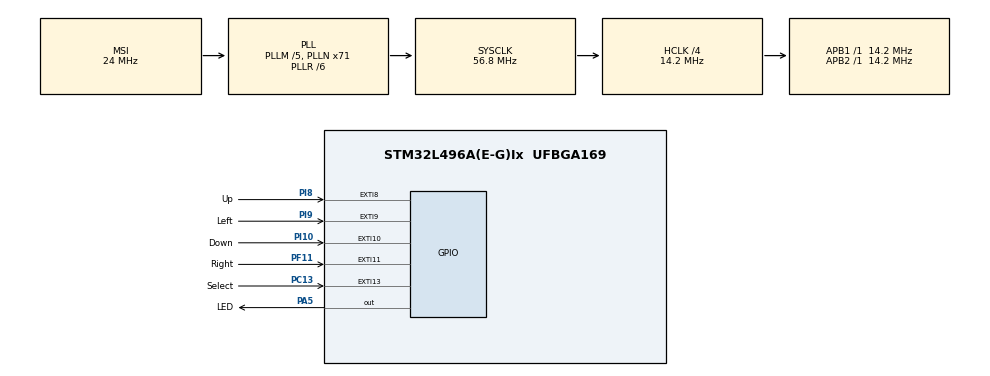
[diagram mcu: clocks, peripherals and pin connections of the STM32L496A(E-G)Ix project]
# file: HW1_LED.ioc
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Mcu.Family=STM32L4
Mcu.Name=STM32L496A(E-G)Ix
Mcu.Package=UFBGA169
NVIC.EXTI15_10_IRQn=true\:0\:0\:false\:false\:true\:true\:true\:true
NVIC.EXTI9_5_IRQn=true\:0\:0\:false\:false\:true\:true\:true\:true
NVIC.PVD_PVM_IRQn=true\:0\:0\:false\:false\:true\:true\:true\:true
NVIC.PriorityGroup=NVIC_PRIORITYGROUP_4
PA5.GPIO_Label=LED
PA5.GPIO_PuPd=GPIO_NOPULL
PA5.GPIO_Speed=GPIO_SPEED_FREQ_HIGH
PA5.Signal=GPIO_Output
PC13.GPIO_Label=Select
PC13.GPIO_PuPd=GPIO_PULLDOWN
PC13.Signal=GPXTI13
PF11.GPIO_Label=Right 
PF11.GPIO_PuPd=GPIO_PULLDOWN
PF11.Signal=GPXTI11
PI10.GPIO_Label=Down 
PI10.GPIO_PuPd=GPIO_PULLDOWN
PI10.Signal=GPXTI10
PI8.GPIO_Label=Up 
PI8.GPIO_PuPd=GPIO_PULLDOWN
PI8.Signal=GPXTI8
PI9.GPIO_Label=Left
PI9.GPIO_PuPd=GPIO_PULLDOWN
PI9.Signal=GPXTI9
ProjectManager.HeapSize=0x200
ProjectManager.StackSize=0x400
ProjectManager.TargetToolchain=STM32CubeIDE
RCC.ADCFreq_Value=48000000
RCC.AHBCLKDivider=RCC_SYSCLK_DIV4
RCC.AHBFreq_Value=14200000
RCC.APB1Freq_Value=14200000
RCC.APB1TimFreq_Value=14200000
RCC.APB2Freq_Value=14200000
RCC.APB2TimFreq_Value=14200000
RCC.CortexFreq_Value=14200000
RCC.HCLKFreq_Value=14200000
RCC.HSE_VALUE=8000000
RCC.HSI48_VALUE=48000000
RCC.HSI_VALUE=16000000
RCC.LSE_VALUE=32768
RCC.MSIClockRange=RCC_MSIRANGE_9
RCC.MSI_VALUE=24000000
RCC.PLLM=5
RCC.PLLN=71
RCC.PLLR=RCC_PLLR_DIV6
RCC.PLLSAI1N=20
RCC.SYSCLKFreq_VALUE=56800000
RCC.SYSCLKSource=RCC_SYSCLKSOURCE_PLLCLK
RCC.USBFreq_Value=48000000
RCC.VCOOutputFreq_Value=340800000
board=STM32L496G-DISCO

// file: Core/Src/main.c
/* USER CODE BEGIN Header */
/**
  ******************************************************************************
  * @file           : main.c
  * @brief          : Main program body
  ******************************************************************************
  * @attention
  *
  * Copyright (c) 2022 STMicroelectronics.
  * All rights reserved.
  *
  * This software is licensed under terms that can be found in the LICENSE file
  * in the root directory of this software component.
  * If no LICENSE file comes with this software, it is provided AS-IS.
  *
  ******************************************************************************
  */
/* USER CODE END Header */
#include "main.h"

void SystemClock_Config(void);
static void MX_GPIO_Init(void);

int main(void)
{

  /* MCU Configuration--------------------------------------------------------*/

  /* Reset of all peripherals, Initializes the Flash interface and the Systick. */
  HAL_Init();

  /* Configure the system clock */
  SystemClock_Config();

  /* Initialize all configured peripherals */
  MX_GPIO_Init();

  /* Infinite loop */
  while (1)
  {

  }
}

void SystemClock_Config(void)
{
  RCC_OscInitTypeDef RCC_OscInitStruct = {0};
  RCC_ClkInitTypeDef RCC_ClkInitStruct = {0};

  /** Configure the main internal regulator output voltage
  */
  if (HAL_PWREx_ControlVoltageScaling(PWR_REGULATOR_VOLTAGE_SCALE1) != HAL_OK)
  {
    Error_Handler();
  }

  /** Initializes the RCC Oscillators according to the specified parameters
  * in the RCC_OscInitTypeDef structure.
  */
  RCC_OscInitStruct.OscillatorType = RCC_OSCILLATORTYPE_MSI;
  RCC_OscInitStruct.MSIState = RCC_MSI_ON;
  RCC_OscInitStruct.MSICalibrationValue = 0;
  RCC_OscInitStruct.MSIClockRange = RCC_MSIRANGE_9;
  RCC_OscInitStruct.PLL.PLLState = RCC_PLL_ON;
  RCC_OscInitStruct.PLL.PLLSource = RCC_PLLSOURCE_MSI;
  RCC_OscInitStruct.PLL.PLLM = 5;
  RCC_OscInitStruct.PLL.PLLN = 71;
  RCC_OscInitStruct.PLL.PLLP = RCC_PLLP_DIV2;
  RCC_OscInitStruct.PLL.PLLQ = RCC_PLLQ_DIV2;
  RCC_OscInitStruct.PLL.PLLR = RCC_PLLR_DIV6;
  if (HAL_RCC_OscConfig(&RCC_OscInitStruct) != HAL_OK)
  {
    Error_Handler();
  }

  /** Initializes the CPU, AHB and APB buses clocks
  */
  RCC_ClkInitStruct.ClockType = RCC_CLOCKTYPE_HCLK|RCC_CLOCKTYPE_SYSCLK
                              |RCC_CLOCKTYPE_PCLK1|RCC_CLOCKTYPE_PCLK2;
  RCC_ClkInitStruct.SYSCLKSource = RCC_SYSCLKSOURCE_PLLCLK;
  RCC_ClkInitStruct.AHBCLKDivider = RCC_SYSCLK_DIV4;
  RCC_ClkInitStruct.APB1CLKDivider = RCC_HCLK_DIV1;
  RCC_ClkInitStruct.APB2CLKDivider = RCC_HCLK_DIV1;

  if (HAL_RCC_ClockConfig(&RCC_ClkInitStruct, FLASH_LATENCY_0) != HAL_OK)
  {
    Error_Handler();
  }
}

static void MX_GPIO_Init(void)
{
  GPIO_InitTypeDef GPIO_InitStruct = {0};

  /* GPIO Ports Clock Enable */
  __HAL_RCC_GPIOI_CLK_ENABLE();
  __HAL_RCC_GPIOC_CLK_ENABLE();
  __HAL_RCC_GPIOA_CLK_ENABLE();
  __HAL_RCC_GPIOF_CLK_ENABLE();

  /*Configure GPIO pin Output Level */
  HAL_GPIO_WritePin(LED_GPIO_Port, LED_Pin, GPIO_PIN_RESET);

  /*Configure GPIO pins : Down_Pin Left_Pin Up_Pin */
  GPIO_InitStruct.Pin = Down_Pin|Left_Pin|Up_Pin;
  GPIO_InitStruct.Mode = GPIO_MODE_IT_RISING;
  GPIO_InitStruct.Pull = GPIO_PULLDOWN;
  HAL_GPIO_Init(GPIOI, &GPIO_InitStruct);

  /*Configure GPIO pin : Select_Pin */
  GPIO_InitStruct.Pin = Select_Pin;
  GPIO_InitStruct.Mode = GPIO_MODE_IT_RISING;
  GPIO_InitStruct.Pull = GPIO_PULLDOWN;
  HAL_GPIO_Init(Select_GPIO_Port, &GPIO_InitStruct);

  /*Configure GPIO pin : LED_Pin */
  GPIO_InitStruct.Pin = LED_Pin;
  GPIO_InitStruct.Mode = GPIO_MODE_OUTPUT_PP;
  GPIO_InitStruct.Pull = GPIO_NOPULL;
  GPIO_InitStruct.Speed = GPIO_SPEED_FREQ_HIGH;
  HAL_GPIO_Init(LED_GPIO_Port, &GPIO_InitStruct);

  /*Configure GPIO pin : Right_Pin */
  GPIO_InitStruct.Pin = Right_Pin;
  GPIO_InitStruct.Mode = GPIO_MODE_IT_RISING;
  GPIO_InitStruct.Pull = GPIO_PULLDOWN;
  HAL_GPIO_Init(Right_GPIO_Port, &GPIO_InitStruct);

  /* EXTI interrupt init*/
  HAL_NVIC_SetPriority(EXTI9_5_IRQn, 0, 0);
  HAL_NVIC_EnableIRQ(EXTI9_5_IRQn);

  HAL_NVIC_SetPriority(EXTI15_10_IRQn, 0, 0);
  HAL_NVIC_EnableIRQ(EXTI15_10_IRQn);

}

/* USER CODE BEGIN 4 */
void HAL_GPIO_EXTI_Callback(uint16_t GPIO_Pin)
{
  /* Prevent unused argument(s) compilation warning */
	if(GPIO_Pin == Select_Pin){
		HAL_GPIO_TogglePin(LED_GPIO_Port, LED_Pin);
//		HAL_GPIO_WritePin(LED_GPIO_Port, LED_Pin, SET);
	}
}
/* USER CODE END 4 */

void Error_Handler(void)
{
  __disable_irq();
  while (1)
  {
  }
}
